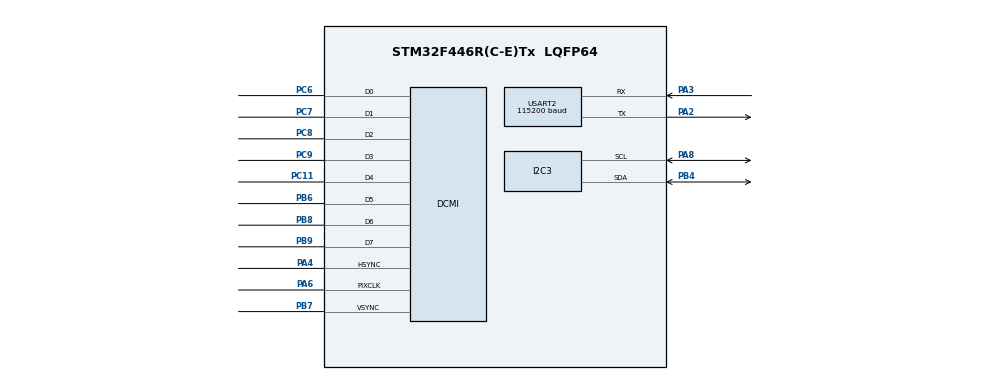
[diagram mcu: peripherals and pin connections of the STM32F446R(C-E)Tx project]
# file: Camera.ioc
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Mcu.Family=STM32F4
PA6.Mode=Slave_8_bits_External_Synchro
RCC.CortexFreq_Value=16000000
PC11.Signal=DCMI_D4
USART2.Parity=PARITY_NONE
PC8.Signal=DCMI_D2
PC6.Signal=DCMI_D0
NVIC.DMA2_Stream1_IRQn=true\:0\:0\:false\:false\:true\:false\:true
USART2.BaudRate=115200
ProjectManager.StackSize=0x400
Dma.DCMI.0.FIFOMode=DMA_FIFOMODE_DISABLE
Dma.DCMI.0.MemDataAlignment=DMA_MDATAALIGN_WORD
PA3.Mode=Asynchronous
PA13.Signal=SYS_JTMS-SWDIO
Dma.DCMI.0.MemInc=DMA_MINC_ENABLE
PA4.Mode=Slave_8_bits_External_Synchro
ProjectManager.TargetToolchain=STM32CubeIDE
Dma.DCMI.0.PeriphDataAlignment=DMA_PDATAALIGN_WORD
PC6.Mode=Slave_8_bits_External_Synchro
PB9.Mode=Slave_8_bits_External_Synchro
Dma.DCMI.0.Instance=DMA2_Stream1
Dma.DCMI.0.Mode=DMA_CIRCULAR
PB6.Signal=DCMI_D5
PC7.Signal=DCMI_D1
PB6.Mode=Slave_8_bits_External_Synchro
RCC.USBFreq_Value=96000000
board=custom
PC7.GPIO_Speed=GPIO_SPEED_FREQ_VERY_HIGH
RCC.VCOOutputFreq_Value=192000000
PA4.GPIO_Speed=GPIO_SPEED_FREQ_VERY_HIGH
DCMI.PCKPolarity=DCMI_PCKPOLARITY_RISING
PB4.Mode=I2C
PA14.Mode=Serial_Wire
PC9.Mode=Slave_8_bits_External_Synchro
PC11.GPIO_Speed=GPIO_SPEED_FREQ_VERY_HIGH
PB7.Signal=DCMI_VSYNC
PA8.Signal=I2C3_SCL
PA13.Mode=Serial_Wire
Mcu.Name=STM32F446R(C-E)Tx
PA2.Signal=USART2_TX
PC8.Mode=Slave_8_bits_External_Synchro
PA4.Signal=DCMI_HSYNC
Mcu.Package=LQFP64
PB9.Signal=DCMI_D7
PA6.Signal=DCMI_PIXCLK
Dma.DCMI.0.Direction=DMA_PERIPH_TO_MEMORY
USART2.VirtualMode=VM_ASYNC
PB7.Mode=Slave_8_bits_External_Synchro
PA14.Signal=SYS_JTCK-SWCLK
ProjectManager.HeapSize=0x200
PC8.GPIO_Speed=GPIO_SPEED_FREQ_VERY_HIGH
PC11.Mode=Slave_8_bits_External_Synchro
PC9.GPIO_Speed=GPIO_SPEED_FREQ_VERY_HIGH
NVIC.PriorityGroup=NVIC_PRIORITYGROUP_4
PB9.GPIO_Speed=GPIO_SPEED_FREQ_VERY_HIGH
PB8.Mode=Slave_8_bits_External_Synchro
PA2.Mode=Asynchronous
PB8.Signal=DCMI_D6
PA8.Mode=I2C
Dma.DCMI.0.PeriphInc=DMA_PINC_DISABLE
PC9.Signal=DCMI_D3
NVIC.DCMI_IRQn=true\:0\:0\:false\:false\:true\:true\:true
PA6.GPIO_Speed=GPIO_SPEED_FREQ_VERY_HIGH
PC7.Mode=Slave_8_bits_External_Synchro
PB6.GPIO_Speed=GPIO_SPEED_FREQ_VERY_HIGH
Dma.Request0=DCMI
PB8.GPIO_Speed=GPIO_SPEED_FREQ_VERY_HIGH
PC6.GPIO_Speed=GPIO_SPEED_FREQ_VERY_HIGH
PB4.Signal=I2C3_SDA
PA3.Signal=USART2_RX
Dma.DCMI.0.Priority=DMA_PRIORITY_VERY_HIGH
PB7.GPIO_Speed=GPIO_SPEED_FREQ_VERY_HIGH

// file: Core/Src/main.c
/* USER CODE BEGIN Header */
/**
  ******************************************************************************
  * @file           : main.c
  * @brief          : Main program body
  ******************************************************************************
  * @attention
  *
  * <h2><center>&copy; Copyright (c) 2024 STMicroelectronics.
  * All rights reserved.</center></h2>
  *
  * This software component is licensed by ST under BSD 3-Clause license,
  * the "License"; You may not use this file except in compliance with the
  * License. You may obtain a copy of the License at:
  *                        opensource.org/licenses/BSD-3-Clause
  *
  ******************************************************************************
  */
/* USER CODE END Header */
#include "main.h"

DCMI_HandleTypeDef hdcmi;
DMA_HandleTypeDef hdma_dcmi;

I2C_HandleTypeDef hi2c3;

UART_HandleTypeDef huart2;

void SystemClock_Config(void);
static void MX_GPIO_Init(void);
static void MX_DMA_Init(void);
static void MX_DCMI_Init(void);
static void MX_USART2_UART_Init(void);
static void MX_I2C3_Init(void);

int main(void)
{

  /* MCU Configuration--------------------------------------------------------*/

  /* Reset of all peripherals, Initializes the Flash interface and the Systick. */
  HAL_Init();

  /* Configure the system clock */
  SystemClock_Config();

  /* Initialize all configured peripherals */
  MX_GPIO_Init();
  MX_DMA_Init();
  MX_DCMI_Init();
  MX_USART2_UART_Init();
  MX_I2C3_Init();
  /* USER CODE BEGIN 2 */
  Camera_init();
  /* USER CODE END 2 */

  /* Infinite loop */
  while (1)
  {

  }
}

void SystemClock_Config(void)
{
  RCC_OscInitTypeDef RCC_OscInitStruct = {0};
  RCC_ClkInitTypeDef RCC_ClkInitStruct = {0};

  /** Configure the main internal regulator output voltage
  */
  __HAL_RCC_PWR_CLK_ENABLE();
  __HAL_PWR_VOLTAGESCALING_CONFIG(PWR_REGULATOR_VOLTAGE_SCALE3);
  /** Initializes the RCC Oscillators according to the specified parameters
  * in the RCC_OscInitTypeDef structure.
  */
  RCC_OscInitStruct.OscillatorType = RCC_OSCILLATORTYPE_HSI;
  RCC_OscInitStruct.HSIState = RCC_HSI_ON;
  RCC_OscInitStruct.HSICalibrationValue = RCC_HSICALIBRATION_DEFAULT;
  RCC_OscInitStruct.PLL.PLLState = RCC_PLL_NONE;
  if (HAL_RCC_OscConfig(&RCC_OscInitStruct) != HAL_OK)
  {
    Error_Handler();
  }
  /** Initializes the CPU, AHB and APB buses clocks
  */
  RCC_ClkInitStruct.ClockType = RCC_CLOCKTYPE_HCLK|RCC_CLOCKTYPE_SYSCLK
                              |RCC_CLOCKTYPE_PCLK1|RCC_CLOCKTYPE_PCLK2;
  RCC_ClkInitStruct.SYSCLKSource = RCC_SYSCLKSOURCE_HSI;
  RCC_ClkInitStruct.AHBCLKDivider = RCC_SYSCLK_DIV1;
  RCC_ClkInitStruct.APB1CLKDivider = RCC_HCLK_DIV1;
  RCC_ClkInitStruct.APB2CLKDivider = RCC_HCLK_DIV1;

  if (HAL_RCC_ClockConfig(&RCC_ClkInitStruct, FLASH_LATENCY_0) != HAL_OK)
  {
    Error_Handler();
  }
}

static void MX_DCMI_Init(void)
{

  hdcmi.Instance = DCMI;
  hdcmi.Init.SynchroMode = DCMI_SYNCHRO_HARDWARE;
  hdcmi.Init.PCKPolarity = DCMI_PCKPOLARITY_RISING;
  hdcmi.Init.VSPolarity = DCMI_VSPOLARITY_LOW;
  hdcmi.Init.HSPolarity = DCMI_HSPOLARITY_LOW;
  hdcmi.Init.CaptureRate = DCMI_CR_ALL_FRAME;
  hdcmi.Init.ExtendedDataMode = DCMI_EXTEND_DATA_8B;
  hdcmi.Init.JPEGMode = DCMI_JPEG_DISABLE;
  hdcmi.Init.ByteSelectMode = DCMI_BSM_ALL;
  hdcmi.Init.ByteSelectStart = DCMI_OEBS_ODD;
  hdcmi.Init.LineSelectMode = DCMI_LSM_ALL;
  hdcmi.Init.LineSelectStart = DCMI_OELS_ODD;
  if (HAL_DCMI_Init(&hdcmi) != HAL_OK)
  {
    Error_Handler();
  }

}

static void MX_I2C3_Init(void)
{

  hi2c3.Instance = I2C3;
  hi2c3.Init.ClockSpeed = 100000;
  hi2c3.Init.DutyCycle = I2C_DUTYCYCLE_2;
  hi2c3.Init.OwnAddress1 = 0;
  hi2c3.Init.AddressingMode = I2C_ADDRESSINGMODE_7BIT;
  hi2c3.Init.DualAddressMode = I2C_DUALADDRESS_DISABLE;
  hi2c3.Init.OwnAddress2 = 0;
  hi2c3.Init.GeneralCallMode = I2C_GENERALCALL_DISABLE;
  hi2c3.Init.NoStretchMode = I2C_NOSTRETCH_DISABLE;
  if (HAL_I2C_Init(&hi2c3) != HAL_OK)
  {
    Error_Handler();
  }

}

static void MX_USART2_UART_Init(void)
{

  huart2.Instance = USART2;
  huart2.Init.BaudRate = 115200;
  huart2.Init.WordLength = UART_WORDLENGTH_8B;
  huart2.Init.StopBits = UART_STOPBITS_1;
  huart2.Init.Parity = UART_PARITY_NONE;
  huart2.Init.Mode = UART_MODE_TX_RX;
  huart2.Init.HwFlowCtl = UART_HWCONTROL_NONE;
  huart2.Init.OverSampling = UART_OVERSAMPLING_16;
  if (HAL_UART_Init(&huart2) != HAL_OK)
  {
    Error_Handler();
  }

}

static void MX_DMA_Init(void)
{

  /* DMA controller clock enable */
  __HAL_RCC_DMA2_CLK_ENABLE();

  /* DMA interrupt init */
  /* DMA2_Stream1_IRQn interrupt configuration */
  HAL_NVIC_SetPriority(DMA2_Stream1_IRQn, 0, 0);
  HAL_NVIC_EnableIRQ(DMA2_Stream1_IRQn);

}

static void MX_GPIO_Init(void)
{

  /* GPIO Ports Clock Enable */
  __HAL_RCC_GPIOA_CLK_ENABLE();
  __HAL_RCC_GPIOC_CLK_ENABLE();
  __HAL_RCC_GPIOB_CLK_ENABLE();

}

void Error_Handler(void)
{
  __disable_irq();
  while (1)
  {
  }
}

/************************ (C) COPYRIGHT STMicroelectronics *****END OF FILE****/
